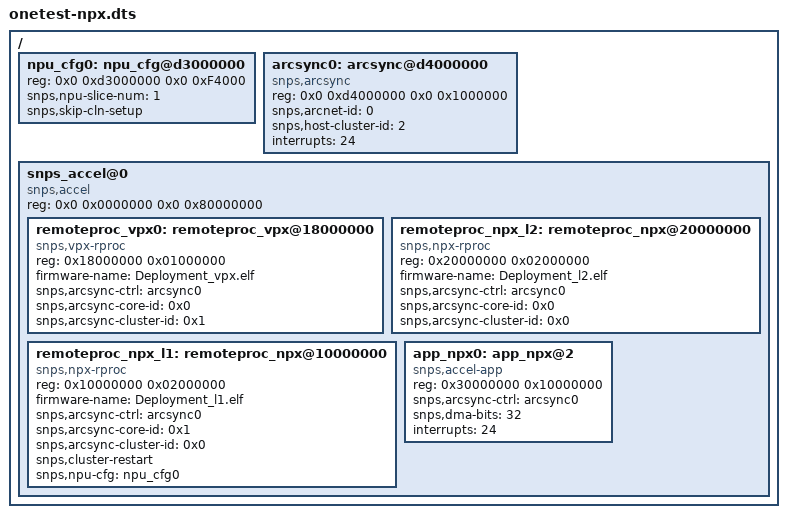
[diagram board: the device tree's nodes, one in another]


/ {
	npu_cfg0: npu_cfg@d3000000 {
		reg = <0x0 0xd3000000 0x0 0xF4000>;
		snps,npu-slice-num = <1>;
		snps,skip-cln-setup;
	};

	arcsync0: arcsync@d4000000 {
		compatible = "snps,arcsync";
		reg = <0x0 0xd4000000 0x0 0x1000000>;
		snps,arcnet-id = <0>;
		snps,host-cluster-id = <2>;
		interrupts = <24>;
	};

	snps_accel@0 {
		compatible = "snps,accel", "simple-bus";
		#address-cells = <1>;
		#size-cells = <1>;
		reg = <0x0 0x0000000 0x0 0x80000000>;
		ranges = <0x0 0x0 0x0 0x80000000>;

		remoteproc_vpx0: remoteproc_vpx@18000000 {
			compatible = "snps,vpx-rproc";
			reg = <0x18000000 0x01000000>;
			firmware-name = "Deployment_vpx.elf";
			snps,arcsync-ctrl = <&arcsync0>;
			snps,arcsync-core-id = <0x0>;
			snps,arcsync-cluster-id = <0x1>;
		};

		remoteproc_npx_l2: remoteproc_npx@20000000 {
			compatible = "snps,npx-rproc";
			reg = <0x20000000 0x02000000>;
			firmware-name = "Deployment_l2.elf";
			snps,arcsync-ctrl = <&arcsync0>;
			snps,arcsync-core-id = <0x0>;
			snps,arcsync-cluster-id = <0x0>;
		};

		remoteproc_npx_l1: remoteproc_npx@10000000 {
			compatible = "snps,npx-rproc";
			reg = <0x10000000 0x02000000>;
			firmware-name = "Deployment_l1.elf";
			snps,arcsync-ctrl = <&arcsync0>;
			snps,arcsync-core-id = <0x1>;
			snps,arcsync-cluster-id = <0x0>;
			snps,cluster-restart;
			snps,npu-cfg = <&npu_cfg0>;
		};

		app_npx0: app_npx@2 {
			compatible = "snps,accel-app";
			reg = <0x30000000 0x10000000>;
			snps,arcsync-ctrl = <&arcsync0>;
			snps,dma-bits = <32>;
			interrupts = <24>;
		};
	};
};
